# AT32F413xx_v2 register map
Vendor: Keil; Series: AT32F413; File version: 1.0
CPU: CM4 r0p1, little endian, no MPU, FPU, 4 interrupt priority bits
Registers are 32-bit, read-write, reset 0x0 unless marked. A register's access mark holds for its fields unless they carry their own. Offsets are from the block's base; [hi:lo] are bit positions; {n}, {i} and the like mark numbered series; 'fields as' and 'values as' point back to an identical list.

## USART1 — Universal synchronous asynchronous receiver transmitter
Base 0x40013800
Same registers: USART2 0x40004400, USART3 0x40004800, UART4 0x40004C00, UART5 0x40005000
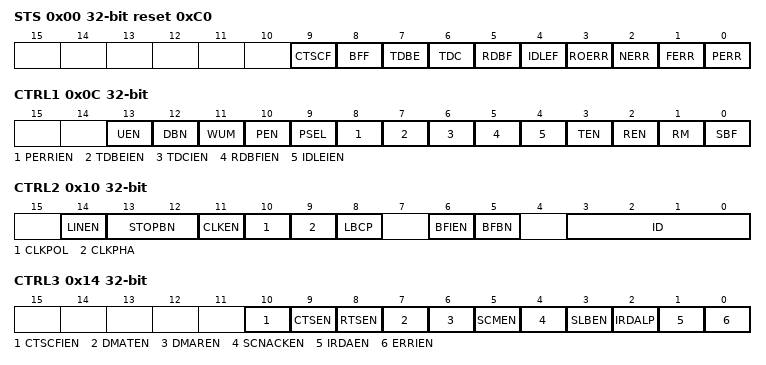
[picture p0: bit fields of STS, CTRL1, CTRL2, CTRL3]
0x00 STS reset 0xC0 — Status register
  [9] CTSCF — CTS change flag
  [8] BFF — Break frame flag
  [7] TDBE ro — Transmit data buffer empty
  [6] TDC — Transmit data complete
  [5] RDBF — Receive data buffer full
  [4] IDLEF ro — IDLE flag
  [3] ROERR ro — Receiver overflow error
  [2] NERR ro — Noise error
  [1] FERR ro — Framing error
  [0] PERR ro — Parity error
0x04 DT — Data register
  [8:0] DT — Data value
0x08 BAUDR — Baud rate register
  [15:0] DIV — Division
0x0C CTRL1 — Control register 1
  [13] UEN — USART enable
  [12] DBN — Data bit num
  [11] WUM — Wake up mode
  [10] PEN — Parity enable
  [9] PSEL — Parity selection
  [8] PERRIEN — PERR interrupt enable
  [7] TDBEIEN — TDBE interrupt enable
  [6] TDCIEN — TDC interrupt enable
  [5] RDBFIEN — RDBF interrupt enable
  [4] IDLEIEN — IDLE interrupt enable
  [3] TEN — Transmitter enable
  [2] REN — Receiver enable
  [1] RM — Receiver mute
  [0] SBF — Send break frame
0x10 CTRL2 — Control register 2
  [14] LINEN — LIN mode enable
  [13:12] STOPBN — STOP bit num
  [11] CLKEN — Clock enable
  [10] CLKPOL — Clock polarity
  [9] CLKPHA — Clock phase
  [8] LBCP — Last bit clock pulse
  [6] BFIEN — Break frame interrupt enable
  [5] BFBN — Break frame bit num
  [3:0] ID — USART identification
0x14 CTRL3 — Control register 3
  [10] CTSCFIEN — CTSCF interrupt enable
  [9] CTSEN — CTS enable
  [8] RTSEN — RTS enable
  [7] DMATEN — DMA transmitter enable
  [6] DMAREN — DMA receiver enable
  [5] SCMEN — Smartcard mode enable
  [4] SCNACKEN — Smartcard NACK enable
  [3] SLBEN — Single line bidirectional half-duplex enable
  [2] IRDALP — IrDA low-power mode
  [1] IRDAEN — IrDA enable
  [0] ERRIEN — Error interrupt enable
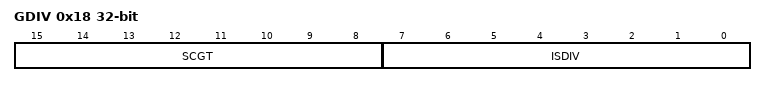
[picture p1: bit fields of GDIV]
0x18 GDIV — Guard time and division register
  [15:8] SCGT — Smart card guard time value
  [7:0] ISDIV — IrDA/smartcard division value

## DEBUG — Debug support
Base 0xE0042000
0x00 IDCODE ro — DEBUG_IDCODE
  [31:0] PID
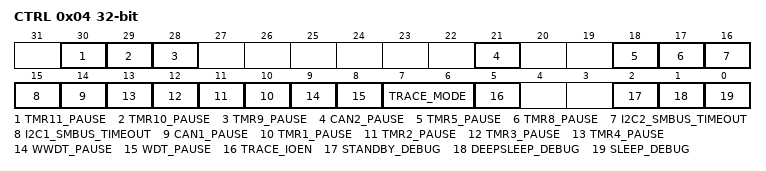
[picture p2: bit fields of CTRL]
0x04 CTRL — DEBUG_CTRL
  [30] TMR11_PAUSE, [29] TMR10_PAUSE, [28] TMR9_PAUSE, [21] CAN2_PAUSE, [18] TMR5_PAUSE, [17] TMR8_PAUSE, [16] I2C2_SMBUS_TIMEOUT, [15] I2C1_SMBUS_TIMEOUT, [14] CAN1_PAUSE, [n+9] TMR{n}_PAUSE (n=1..4), [9] WWDT_PAUSE, [8] WDT_PAUSE, [7:6] TRACE_MODE, [5] TRACE_IOEN, [2] STANDBY_DEBUG, [1] DEEPSLEEP_DEBUG, [0] SLEEP_DEBUG

## CRC — CRC calculation unit
Base 0x40023000
0x00 DT reset 0xFFFFFFFF — Data register
  [31:0] DT — Data Register
0x04 CDT — Common data register
  [0] CDT — Common Data
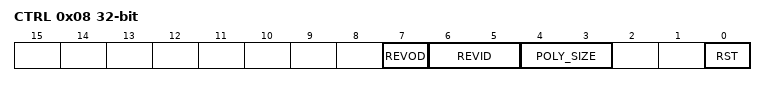
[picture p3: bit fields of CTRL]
0x08 CTRL — Control register
  [7] REVOD — Reverse output data
  [6:5] REVID — Reverse input data
  [4:3] POLY_SIZE — Polynomial size
  [0] RST — Reset bit
0x10 IDT reset 0xFFFFFFFF — Initial data register
  [31:0] IDT — Initial Data
0x14 POLY reset 0x4C11DB7 — Polynomial coefficient register
  [31:0] POLY — polynomial coefficient

## FLASH — Flash memory controler
Base 0x40022000
0x00 PSR reset 0x30 — Performance selection register
0x04 UNLOCK wo
  [31:0] UKVAL — Unlock key value
0x08 USD_UNLOCK wo
  [31:0] USD_UKVAL — User system data Unlock key value
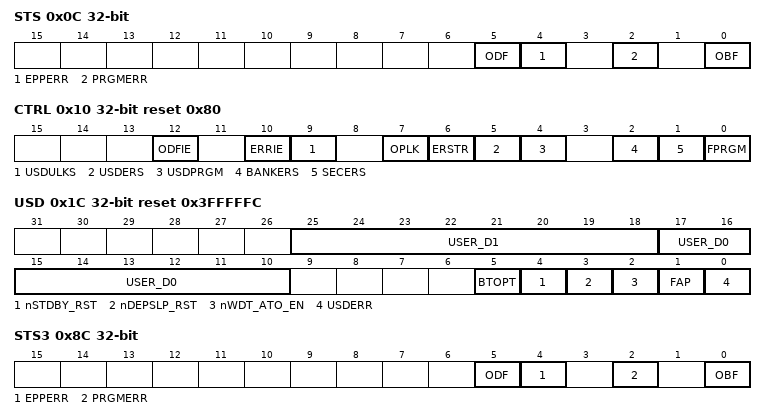
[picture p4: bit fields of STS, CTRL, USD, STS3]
0x0C STS — Status register
  [5] ODF — Operate done flag
  [4] EPPERR — Erase/program protection error
  [2] PRGMERR — program error
  [0] OBF ro — Operate busy flag
0x10 CTRL reset 0x80 — Control register
  [12] ODFIE — Operation done flag interrupt enable
  [10] ERRIE — Error interrupt enable
  [9] USDULKS — User system data unlock success
  [7] OPLK — Operation lock
  [6] ERSTR — Erasing start
  [5] USDERS — User system data erase
  [4] USDPRGM — User system data program
  [2] BANKERS — Bank erase
  [1] SECERS — Sector erase
  [0] FPRGM — Flash program
0x14 ADDR wo — Address register
  [31:0] FA — Flash Address
0x1C USD ro reset 0x3FFFFFC — User system data register
  [25:18] USER_D1 — User data 1
  [17:10] USER_D0 — User data 0
  [5] BTOPT — boot option
  [4] nSTDBY_RST — Standby reset
  [3] nDEPSLP_RST — Deepsleep reset
  [2] nWDT_ATO_EN — WDT auto enable
  [1] FAP — FLASH access protection
  [0] USDERR — User system data error
0x20 EPPS ro reset 0xFFFFFFFF — Erase/program protection status register
  [31:0] EPPS — Erase/program protection status
0x84 UNLOCK3 wo
  [31:0] UKVAL — Unlock key value
0x88 SELECT wo
  [31:0] SELECT — spim type selection
0x8C STS3 — Status 3 register
  fields as STS
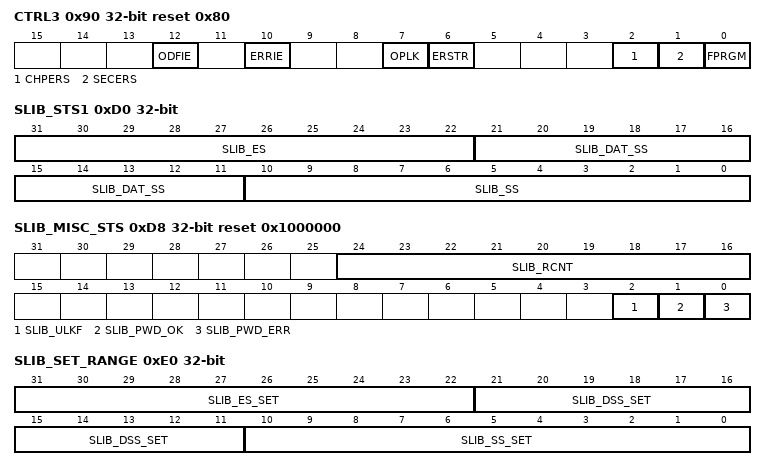
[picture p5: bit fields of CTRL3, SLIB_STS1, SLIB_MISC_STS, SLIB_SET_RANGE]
0x90 CTRL3 reset 0x80 — Control 3 register
  [12] ODFIE — Operation done flag interrupt enable
  [10] ERRIE — Error interrupt enable
  [7] OPLK — Operation lock
  [6] ERSTR — Erasing start
  [2] CHPERS — Chip erase
  [1] SECERS — Sector erase
  [0] FPRGM — Flash program
0x94 ADDR3 wo — Address 3 register
  [31:0] FA — Flash Address
0x98 DA wo — Spim decryption address
  [31:0] FDA — Flash decryption address
0xCC SLIB_STS0 — sLib status 0 register
  [3] SLIB_ENF ro — sLib enabled flag
0xD0 SLIB_STS1 — sLib status 1 register
  [31:22] SLIB_ES ro — sLib end sector
  [21:11] SLIB_DAT_SS ro — sLib data start sector
  [10:0] SLIB_SS ro — sLib start sector
0xD4 SLIB_PWD_CLR wo — SLIB password clear register
  [31:0] SLIB_PCLR_VAL — sLib password clear value
0xD8 SLIB_MISC_STS reset 0x1000000 — sLib misc status register
  [24:16] SLIB_RCNT ro — sLib remaining count
  [2] SLIB_ULKF ro — sLib unlock flag
  [1] SLIB_PWD_OK ro — sLib password ok
  [0] SLIB_PWD_ERR ro — sLib password error
0xDC SLIB_SET_PWD wo — sLib password setting register
  [31:0] SLIB_PSET_VAL — sLib password setting val
0xE0 SLIB_SET_RANGE wo — Configure sLib range register
  [31:22] SLIB_ES_SET — sLib end sector setting
  [21:11] SLIB_DSS_SET — sLib data start sector setting
  [10:0] SLIB_SS_SET — sLib start sector setting
0xF0 SLIB_UNLOCK wo
  [31:0] SLIB_UKVAL — sLib unlock key value
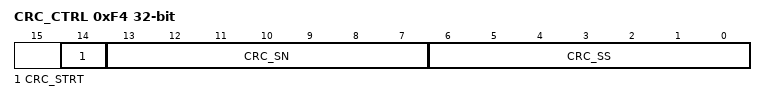
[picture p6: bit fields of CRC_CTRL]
0xF4 CRC_CTRL wo — Flash CRC controler register
  [14] CRC_STRT — CRC start
  [13:7] CRC_SN — CRC sector numbler
  [6:0] CRC_SS — CRC start sector
0xF8 CRC_CHKR ro — FLASH CRC check result register
  [31:0] CRC_CHKR — CRC check result

## NVIC — Nested Vectored Interrupt Controller
Base 0xE000E000
0x04 ICTR ro — Interrupt Controller Type Register
  [3:0] INTLINESNUM — Total number of interrupt lines in groups
0x100 ISER0 — Interrupt Set-Enable Register
  [31:0] SETENA
0x104 ISER1 — Interrupt Set-Enable Register
  [31:0] SETENA
0x180 ICER0 — Interrupt Clear-Enable Register
  [31:0] CLRENA
0x184 ICER1 — Interrupt Clear-Enable Register
  [31:0] CLRENA
0x200 ISPR0 — Interrupt Set-Pending Register
  [31:0] SETPEND
0x204 ISPR1 — Interrupt Set-Pending Register
  [31:0] SETPEND
0x280 ICPR0 — Interrupt Clear-Pending Register
  [31:0] CLRPEND
0x284 ICPR1 — Interrupt Clear-Pending Register
  [31:0] CLRPEND
0x300 IABR0 ro — Interrupt Active Bit Register
  [31:0] ACTIVE
0x304 IABR1 ro — Interrupt Active Bit Register
  [31:0] ACTIVE
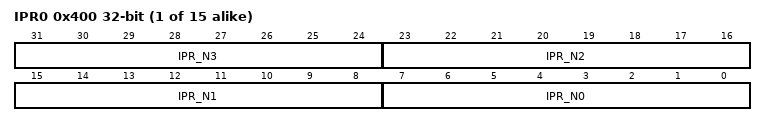
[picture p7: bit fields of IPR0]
{0x400+4i} IPR{i} (i=0..14) — Interrupt Priority Register
  [8n+7:8n] IPR_N{n} (n=0..3)
0xF00 STIR wo — Software Triggered Interrupt Register
  [8:0] INTID — interrupt to be triggered

## USBFS — Universal serial bus full-speed device interface
Base 0x40005C00
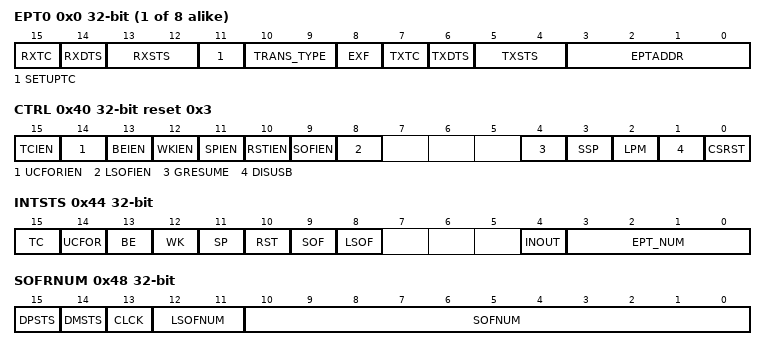
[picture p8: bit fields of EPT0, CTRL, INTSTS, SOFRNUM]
{0x0+4i} EPT{i} (i=0..7) — endpoint {i} register
  [15] RXTC — Rx transaction completed
  [14] RXDTS — Rx data toggle synchronization
  [13:12] RXSTS — Rx Status
  [11] SETUPTC — Setup transaction completed
  [10:9] TRANS_TYPE — Transfer type
  [8] EXF — Endpoint extend function
  [7] TXTC — Tx transaction completed
  [6] TXDTS — Tx data toggle synchronization
  [5:4] TXSTS — Tx status
  [3:0] EPTADDR — Endpoint address
0x40 CTRL reset 0x3 — control register
  [15] TCIEN — transmission completed interrupt enable
  [14] UCFORIEN — USB Core fifo overrun interrupt enable
  [13] BEIEN — Bus error interrupt enable
  [12] WKIEN — Wakeup/Remote wakeup interrupt enable
  [11] SPIEN — Bus suspend mode interrupt enable
  [10] RSTIEN — Bus reset interrupt enable
  [9] SOFIEN — Start of frame interrupt enable
  [8] LSOFIEN — Lost start of frame interrupt enable
  [4] GRESUME — Generate resume request
  [3] SSP — Soft suspend config
  [2] LPM — Low power mode
  [1] DISUSB — Disable usb phy
  [0] CSRST — Core soft reset
0x44 INTSTS — interrupt status register
  [15] TC — transaction completed
  [14] UCFOR — USB core fifo overrun memory
  [13] BE — Bus error
  [12] WK — Wakeup
  [11] SP — Bus suspend
  [10] RST — Bus reset
  [9] SOF — start of frame
  [8] LSOF — Lost start of frame
  [4] INOUT — In/Out transaction
  [3:0] EPT_NUM — Endpoint number
0x48 SOFRNUM — frame number register
  [15] DPSTS — DP status
  [14] DMSTS — DM status
  [13] CLCK — Connect locked
  [12:11] LSOFNUM — Lost start of frame number
  [10:0] SOFNUM — Start of frame number
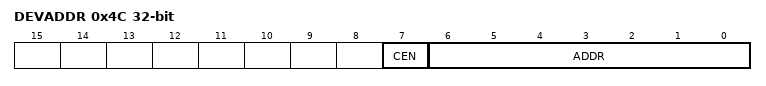
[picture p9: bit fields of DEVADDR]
0x4C DEVADDR — device address
  [7] CEN — USB core enable
  [6:0] ADDR — Host assign device address
0x50 BUFTBL — Buffer table address
  [15:3] BTADDR — Endpoint buffer table start address
0x60 CFG — CFG control register
  [0] SOFOUTEN — SOF output enable

## Notices in the file
Copyright (C) 2012-2014 ARM Limited. All rights reserved.
Purpose: System Viewer Description (SVD) Example (Schema Version 1.1)
This is a description of a none-existent and incomplete device
for demonstration purposes only.
Redistribution and use in source and binary forms, with or without
modification, are permitted provided that the following conditions are met:
- Redistributions of source code must retain the above copyright
notice, this list of conditions and the following disclaimer.
- Redistributions in binary form must reproduce the above copyright
notice, this list of conditions and the following disclaimer in the
documentation and/or other materials provided with the distribution.
- Neither the name of ARM nor the names of its contributors may be used
to endorse or promote products derived from this software without
specific prior written permission.
THIS SOFTWARE IS PROVIDED BY THE COPYRIGHT HOLDERS AND CONTRIBUTORS "AS IS"
AND ANY EXPRESS OR IMPLIED WARRANTIES, INCLUDING, BUT NOT LIMITED TO, THE
IMPLIED WARRANTIES OF MERCHANTABILITY AND FITNESS FOR A PARTICULAR PURPOSE
ARE DISCLAIMED. IN NO EVENT SHALL COPYRIGHT HOLDERS AND CONTRIBUTORS BE
LIABLE FOR ANY DIRECT, INDIRECT, INCIDENTAL, SPECIAL, EXEMPLARY, OR
CONSEQUENTIAL DAMAGES (INCLUDING, BUT NOT LIMITED TO, PROCUREMENT OF
SUBSTITUTE GOODS OR SERVICES; LOSS OF USE, DATA, OR PROFITS; OR BUSINESS
INTERRUPTION) HOWEVER CAUSED AND ON ANY THEORY OF LIABILITY, WHETHER IN
CONTRACT, STRICT LIABILITY, OR TORT (INCLUDING NEGLIGENCE OR OTHERWISE)
ARISING IN ANY WAY OUT OF THE USE OF THIS SOFTWARE, EVEN IF ADVISED OF THE
POSSIBILITY OF SUCH DAMAGE.
